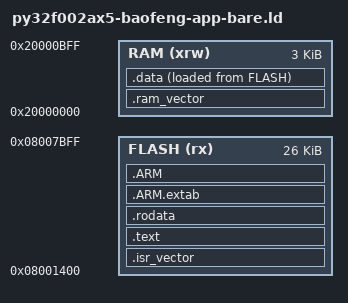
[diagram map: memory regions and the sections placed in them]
/*
******************************************************************************
**
**  File        : LinkerScript.ld
**
**  Abstract    : Linker script for PY32F002A series
**                Set heap size, stack size and stack location according
**                to application requirements.
**                Set memory bank area and size if external memory is used.
**
**  Distribution: The file is distributed “as is,” without any warranty
**                of any kind.
**
*****************************************************************************
*/

/* Entry Point */
ENTRY(Reset_Handler)

/* Highest address of the user mode stack */
_estack = ORIGIN(RAM) + LENGTH(RAM);    /* end of RAM */
/*
  Generate a link error if heap and stack don't fit into RAM.
  These numbers affect the USED size of RAM
*/
_Min_Heap_Size = 0x100;   /* required amount of heap: 256 bytes */
_Min_Stack_Size = 0x200;  /* required amount of stack: 512 bytes */

/* Specify the memory areas */
MEMORY
{
  RAM (xrw)      : ORIGIN = 0x20000000, LENGTH = 3K
  FLASH (rx)     : ORIGIN = 0x08001400, LENGTH = 26K
}

/* Define output sections */
SECTIONS
{
  /* SRAM vector table */
  .ram_vector :
  {
    *(.ram_vector)
  } >RAM

  /* The startup code goes first into FLASH */
  .isr_vector :
  {
    . = ALIGN(4);
    KEEP(*(.isr_vector)) /* Startup code */
    . = ALIGN(4);
  } >FLASH

  /* The program code and other data goes into FLASH */
  .text :
  {
    . = ALIGN(4);
    *(.text)           /* .text sections (code) */
    *(.text*)          /* .text* sections (code) */
    *(.glue_7)         /* glue arm to thumb code */
    *(.glue_7t)        /* glue thumb to arm code */
    *(.eh_frame)
    . = ALIGN(4);
    _etext = .;        /* define a global symbols at end of code */
  } >FLASH

  /* Constant data goes into FLASH */
  .rodata :
  {
    . = ALIGN(4);
    *(.rodata)         /* .rodata sections (constants, strings, etc.) */
    *(.rodata*)        /* .rodata* sections (constants, strings, etc.) */
    . = ALIGN(4);
  } >FLASH

  .ARM.extab   : { *(.ARM.extab* .gnu.linkonce.armextab.*) } >FLASH
  .ARM : {
    __exidx_start = .;
    *(.ARM.exidx*)
    __exidx_end = .;
  } >FLASH

  /* used by the startup to initialize data */
  _sidata = LOADADDR(.data);

  /* Initialized data sections goes into RAM, load LMA copy after code */
  .data : 
  {
    . = ALIGN(4);
    _sdata = .;        /* create a global symbol at data start */
    *(.data)           /* .data sections */
    *(.data*)          /* .data* sections */

    . = ALIGN(4);
    _edata = .;        /* define a global symbol at data end */
  } >RAM AT> FLASH

  /* Remove information from the standard libraries */
  /DISCARD/ :
  {

    *(.init)
    *(.fini)
    libc.a ( * )
    libm.a ( * )
    libgcc.a ( * )
  }

  .ARM.attributes 0 : { *(.ARM.attributes) }
}


